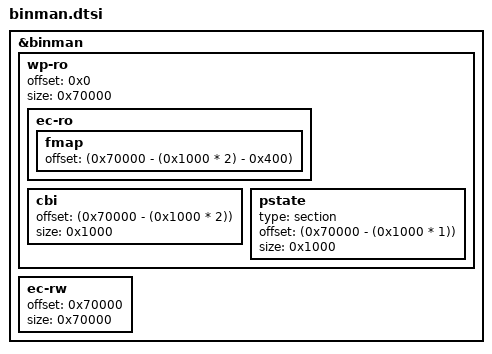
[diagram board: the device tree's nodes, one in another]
/* Copyright 2024 The ChromiumOS Authors
 * Use of this source code is governed by a BSD-style license that can be
 * found in the LICENSE file.
 */
#include <cros/integrated_fwid.dtsi>

/* Brox SKU-4 temporary binman override with space for PDC FW img */

&binman {
	/* The rollback entries are zero-length and can confuse binman
	 * and cause entries to be nested under the CBI section.
	 * Delete these unused entries.
	 */
	/delete-node/ rollback0;
	/delete-node/ rollback1;

	wp-ro {
                offset = <0x0>;
		size = <0x70000>;

		/*
		 * Delete the pstate node so that we can force it to be the
		 * last sub-section. binman doesn't handle sub-sections with
		 * out of order offsets.
		 */
		/delete-node/ pstate;

		ec-ro {
			fmap {
				offset =  <(0x70000 - (0x1000 * 2) - 0x400)>;
				/*
				 * don't specify 'size = <0x400>' here so
				 * it is auto-assigned to the fmap size.
				 */
			};
		};
		cbi {
			offset = <(0x70000 - (0x1000 * 2))>;
			size = <0x1000>;
		};
		pstate {
			type = "section";
			offset = <(0x70000 - (0x1000 * 1))>;
			size = <0x1000>;
		};
	};
        ec-rw {
		offset = <0x70000>;
		size = <0x70000>;
	};
};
